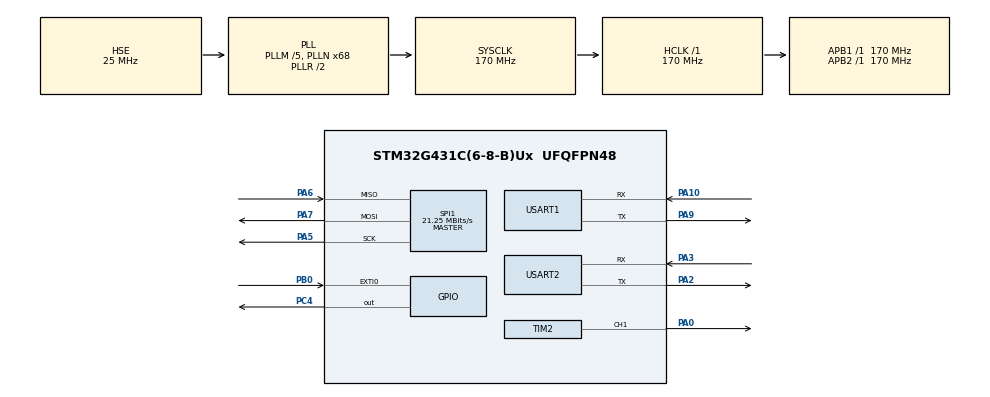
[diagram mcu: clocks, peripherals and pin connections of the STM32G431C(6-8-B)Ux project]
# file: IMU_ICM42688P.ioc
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Mcu.Family=STM32G4
Mcu.Name=STM32G431C(6-8-B)Ux
Mcu.Package=UFQFPN48
NVIC.PriorityGroup=NVIC_PRIORITYGROUP_4
PA0.Signal=S_TIM2_CH1
PA10.Mode=Asynchronous
PA10.Signal=USART1_RX
PA13.Mode=Serial_Wire
PA13.Signal=SYS_JTMS-SWDIO
PA14.Mode=Serial_Wire
PA14.Signal=SYS_JTCK-SWCLK
PA2.Mode=Asynchronous
PA2.Signal=USART2_TX
PA3.Mode=Asynchronous
PA3.Signal=USART2_RX
PA5.Mode=Full_Duplex_Master
PA5.Signal=SPI1_SCK
PA6.Mode=Full_Duplex_Master
PA6.Signal=SPI1_MISO
PA7.Mode=Full_Duplex_Master
PA7.Signal=SPI1_MOSI
PA9.Mode=Asynchronous
PA9.Signal=USART1_TX
PB0.Signal=GPXTI0
PC4.Signal=GPIO_Output
PF0-OSC_IN.Mode=HSE-External-Clock-Source
PF0-OSC_IN.Signal=RCC_OSC_IN
ProjectManager.HeapSize=0x200
ProjectManager.StackSize=0x400
ProjectManager.TargetToolchain=MDK-ARM V5.32
RCC.ADC12Freq_Value=170000000
RCC.AHBFreq_Value=170000000
RCC.APB1Freq_Value=170000000
RCC.APB1TimFreq_Value=170000000
RCC.APB2Freq_Value=170000000
RCC.APB2TimFreq_Value=170000000
RCC.CortexFreq_Value=170000000
RCC.EXTERNAL_CLOCK_VALUE=12288000
RCC.HCLKFreq_Value=170000000
RCC.HSE_VALUE=25000000
RCC.HSI48_VALUE=48000000
RCC.HSI_VALUE=16000000
RCC.LSE_VALUE=32768
RCC.PLLM=RCC_PLLM_DIV5
RCC.PLLN=68
RCC.PLLSourceVirtual=RCC_PLLSOURCE_HSE
RCC.PWR_Regulator_Voltage_Scale=PWR_REGULATOR_VOLTAGE_SCALE1_BOOST
RCC.SYSCLKFreq_VALUE=170000000
RCC.SYSCLKSource=RCC_SYSCLKSOURCE_PLLCLK
RCC.USBFreq_Value=170000000
RCC.VCOOutputFreq_Value=340000000
SH.S_TIM2_CH1.0=TIM2_CH1,PWM Generation1 CH1
SPI1.BaudRatePrescaler=SPI_BAUDRATEPRESCALER_8
SPI1.CLKPhase=SPI_PHASE_2EDGE
SPI1.CLKPolarity=SPI_POLARITY_HIGH
SPI1.CalculateBaudRate=21.25 MBits/s
SPI1.DataSize=SPI_DATASIZE_8BIT
SPI1.Direction=SPI_DIRECTION_2LINES
SPI1.Mode=SPI_MODE_MASTER
SPI1.VirtualType=VM_MASTER
TIM2.Channel-PWM\ Generation1\ CH1=TIM_CHANNEL_1
TIM2.PeriodNoDither=25-1
TIM2.Prescaler=170-1
USART1.VirtualMode-Asynchronous=VM_ASYNC
USART2.VirtualMode-Asynchronous=VM_ASYNC
VP_SYS_VS_DBSignals.Mode=DisableDeadBatterySignals
board=custom

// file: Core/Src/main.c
/* USER CODE BEGIN Header */
/**
  ******************************************************************************
  * @file           : main.c
  * @brief          : Main program body
  ******************************************************************************
  * @attention
  *
  * Copyright (c) 2024 STMicroelectronics.
  * All rights reserved.
  *
  * This software is licensed under terms that can be found in the LICENSE file
  * in the root directory of this software component.
  * If no LICENSE file comes with this software, it is provided AS-IS.
  *
  ******************************************************************************
  */
/* USER CODE END Header */
#include "main.h"

SPI_HandleTypeDef hspi1;

TIM_HandleTypeDef htim2;

UART_HandleTypeDef huart1;
UART_HandleTypeDef huart2;

void SystemClock_Config(void);
static void MX_GPIO_Init(void);
static void MX_SPI1_Init(void);
static void MX_TIM2_Init(void);
static void MX_USART1_UART_Init(void);
static void MX_USART2_UART_Init(void);

int main(void)
{

  /* MCU Configuration--------------------------------------------------------*/

  /* Reset of all peripherals, Initializes the Flash interface and the Systick. */
  HAL_Init();

  /* Configure the system clock */
  SystemClock_Config();

  /* Initialize all configured peripherals */
  MX_GPIO_Init();
  MX_SPI1_Init();
  MX_TIM2_Init();
  MX_USART1_UART_Init();
  MX_USART2_UART_Init();

  /* Infinite loop */
  /* USER CODE BEGIN WHILE */
  while (1)
  {
    HAL_UART_Transmit(&huart1, (uint8_t *)"Hello, World!\r\n", 15, 1000);
    HAL_Delay(1000);
    /* USER CODE END WHILE */

  }
}

void SystemClock_Config(void)
{
  RCC_OscInitTypeDef RCC_OscInitStruct = {0};
  RCC_ClkInitTypeDef RCC_ClkInitStruct = {0};

  /** Configure the main internal regulator output voltage
  */
  HAL_PWREx_ControlVoltageScaling(PWR_REGULATOR_VOLTAGE_SCALE1_BOOST);

  /** Initializes the RCC Oscillators according to the specified parameters
  * in the RCC_OscInitTypeDef structure.
  */
  RCC_OscInitStruct.OscillatorType = RCC_OSCILLATORTYPE_HSE;
  RCC_OscInitStruct.HSEState = RCC_HSE_BYPASS;
  RCC_OscInitStruct.PLL.PLLState = RCC_PLL_ON;
  RCC_OscInitStruct.PLL.PLLSource = RCC_PLLSOURCE_HSE;
  RCC_OscInitStruct.PLL.PLLM = RCC_PLLM_DIV5;
  RCC_OscInitStruct.PLL.PLLN = 68;
  RCC_OscInitStruct.PLL.PLLP = RCC_PLLP_DIV2;
  RCC_OscInitStruct.PLL.PLLQ = RCC_PLLQ_DIV2;
  RCC_OscInitStruct.PLL.PLLR = RCC_PLLR_DIV2;
  if (HAL_RCC_OscConfig(&RCC_OscInitStruct) != HAL_OK)
  {
    Error_Handler();
  }

  /** Initializes the CPU, AHB and APB buses clocks
  */
  RCC_ClkInitStruct.ClockType = RCC_CLOCKTYPE_HCLK|RCC_CLOCKTYPE_SYSCLK
                              |RCC_CLOCKTYPE_PCLK1|RCC_CLOCKTYPE_PCLK2;
  RCC_ClkInitStruct.SYSCLKSource = RCC_SYSCLKSOURCE_PLLCLK;
  RCC_ClkInitStruct.AHBCLKDivider = RCC_SYSCLK_DIV1;
  RCC_ClkInitStruct.APB1CLKDivider = RCC_HCLK_DIV1;
  RCC_ClkInitStruct.APB2CLKDivider = RCC_HCLK_DIV1;

  if (HAL_RCC_ClockConfig(&RCC_ClkInitStruct, FLASH_LATENCY_4) != HAL_OK)
  {
    Error_Handler();
  }
}

static void MX_SPI1_Init(void)
{

  /* SPI1 parameter configuration*/
  hspi1.Instance = SPI1;
  hspi1.Init.Mode = SPI_MODE_MASTER;
  hspi1.Init.Direction = SPI_DIRECTION_2LINES;
  hspi1.Init.DataSize = SPI_DATASIZE_8BIT;
  hspi1.Init.CLKPolarity = SPI_POLARITY_HIGH;
  hspi1.Init.CLKPhase = SPI_PHASE_2EDGE;
  hspi1.Init.NSS = SPI_NSS_SOFT;
  hspi1.Init.BaudRatePrescaler = SPI_BAUDRATEPRESCALER_8;
  hspi1.Init.FirstBit = SPI_FIRSTBIT_MSB;
  hspi1.Init.TIMode = SPI_TIMODE_DISABLE;
  hspi1.Init.CRCCalculation = SPI_CRCCALCULATION_DISABLE;
  hspi1.Init.CRCPolynomial = 7;
  hspi1.Init.CRCLength = SPI_CRC_LENGTH_DATASIZE;
  hspi1.Init.NSSPMode = SPI_NSS_PULSE_DISABLE;
  if (HAL_SPI_Init(&hspi1) != HAL_OK)
  {
    Error_Handler();
  }

}

static void MX_TIM2_Init(void)
{

  TIM_MasterConfigTypeDef sMasterConfig = {0};
  TIM_OC_InitTypeDef sConfigOC = {0};

  htim2.Instance = TIM2;
  htim2.Init.Prescaler = 170-1;
  htim2.Init.CounterMode = TIM_COUNTERMODE_UP;
  htim2.Init.Period = 24;
  htim2.Init.ClockDivision = TIM_CLOCKDIVISION_DIV1;
  htim2.Init.AutoReloadPreload = TIM_AUTORELOAD_PRELOAD_DISABLE;
  if (HAL_TIM_PWM_Init(&htim2) != HAL_OK)
  {
    Error_Handler();
  }
  sMasterConfig.MasterOutputTrigger = TIM_TRGO_RESET;
  sMasterConfig.MasterSlaveMode = TIM_MASTERSLAVEMODE_DISABLE;
  if (HAL_TIMEx_MasterConfigSynchronization(&htim2, &sMasterConfig) != HAL_OK)
  {
    Error_Handler();
  }
  sConfigOC.OCMode = TIM_OCMODE_PWM1;
  sConfigOC.Pulse = 0;
  sConfigOC.OCPolarity = TIM_OCPOLARITY_HIGH;
  sConfigOC.OCFastMode = TIM_OCFAST_DISABLE;
  if (HAL_TIM_PWM_ConfigChannel(&htim2, &sConfigOC, TIM_CHANNEL_1) != HAL_OK)
  {
    Error_Handler();
  }
  HAL_TIM_MspPostInit(&htim2);

}

static void MX_USART1_UART_Init(void)
{

  huart1.Instance = USART1;
  huart1.Init.BaudRate = 115200;
  huart1.Init.WordLength = UART_WORDLENGTH_8B;
  huart1.Init.StopBits = UART_STOPBITS_1;
  huart1.Init.Parity = UART_PARITY_NONE;
  huart1.Init.Mode = UART_MODE_TX_RX;
  huart1.Init.HwFlowCtl = UART_HWCONTROL_NONE;
  huart1.Init.OverSampling = UART_OVERSAMPLING_16;
  huart1.Init.OneBitSampling = UART_ONE_BIT_SAMPLE_DISABLE;
  huart1.Init.ClockPrescaler = UART_PRESCALER_DIV1;
  huart1.AdvancedInit.AdvFeatureInit = UART_ADVFEATURE_NO_INIT;
  if (HAL_UART_Init(&huart1) != HAL_OK)
  {
    Error_Handler();
  }
  if (HAL_UARTEx_SetTxFifoThreshold(&huart1, UART_TXFIFO_THRESHOLD_1_8) != HAL_OK)
  {
    Error_Handler();
  }
  if (HAL_UARTEx_SetRxFifoThreshold(&huart1, UART_RXFIFO_THRESHOLD_1_8) != HAL_OK)
  {
    Error_Handler();
  }
  if (HAL_UARTEx_DisableFifoMode(&huart1) != HAL_OK)
  {
    Error_Handler();
  }

}

static void MX_USART2_UART_Init(void)
{

  huart2.Instance = USART2;
  huart2.Init.BaudRate = 115200;
  huart2.Init.WordLength = UART_WORDLENGTH_8B;
  huart2.Init.StopBits = UART_STOPBITS_1;
  huart2.Init.Parity = UART_PARITY_NONE;
  huart2.Init.Mode = UART_MODE_TX_RX;
  huart2.Init.HwFlowCtl = UART_HWCONTROL_NONE;
  huart2.Init.OverSampling = UART_OVERSAMPLING_16;
  huart2.Init.OneBitSampling = UART_ONE_BIT_SAMPLE_DISABLE;
  huart2.Init.ClockPrescaler = UART_PRESCALER_DIV1;
  huart2.AdvancedInit.AdvFeatureInit = UART_ADVFEATURE_NO_INIT;
  if (HAL_UART_Init(&huart2) != HAL_OK)
  {
    Error_Handler();
  }
  if (HAL_UARTEx_SetTxFifoThreshold(&huart2, UART_TXFIFO_THRESHOLD_1_8) != HAL_OK)
  {
    Error_Handler();
  }
  if (HAL_UARTEx_SetRxFifoThreshold(&huart2, UART_RXFIFO_THRESHOLD_1_8) != HAL_OK)
  {
    Error_Handler();
  }
  if (HAL_UARTEx_DisableFifoMode(&huart2) != HAL_OK)
  {
    Error_Handler();
  }

}

static void MX_GPIO_Init(void)
{
  GPIO_InitTypeDef GPIO_InitStruct = {0};

  /* GPIO Ports Clock Enable */
  __HAL_RCC_GPIOF_CLK_ENABLE();
  __HAL_RCC_GPIOA_CLK_ENABLE();
  __HAL_RCC_GPIOC_CLK_ENABLE();
  __HAL_RCC_GPIOB_CLK_ENABLE();

  /*Configure GPIO pin Output Level */
  HAL_GPIO_WritePin(GPIOC, GPIO_PIN_4, GPIO_PIN_RESET);

  /*Configure GPIO pin : PC4 */
  GPIO_InitStruct.Pin = GPIO_PIN_4;
  GPIO_InitStruct.Mode = GPIO_MODE_OUTPUT_PP;
  GPIO_InitStruct.Pull = GPIO_NOPULL;
  GPIO_InitStruct.Speed = GPIO_SPEED_FREQ_LOW;
  HAL_GPIO_Init(GPIOC, &GPIO_InitStruct);

  /*Configure GPIO pin : PB0 */
  GPIO_InitStruct.Pin = GPIO_PIN_0;
  GPIO_InitStruct.Mode = GPIO_MODE_IT_RISING;
  GPIO_InitStruct.Pull = GPIO_NOPULL;
  HAL_GPIO_Init(GPIOB, &GPIO_InitStruct);

}

void Error_Handler(void)
{
  __disable_irq();
  while (1)
  {
  }
}
